# EFR32BG24A010F1024IM40 register map
Vendor: Silicon Labs; Series: EFR32; File version: B
Registers are 32-bit, read-write, reset 0x0 unless marked. A register's access mark holds for its fields unless they carry their own. Offsets are from the block's base; [hi:lo] are bit positions; {n}, {i} and the like mark numbered series; 'fields as' and 'values as' point back to an identical list.

## HOSTMAILBOX_S — HOSTMAILBOX_S Registers
Base 0x40098000
Same registers: HOSTMAILBOX_NS 0x50098000, RFMAILBOX_S 0xA802C000, RFMAILBOX_NS 0xB802C000
{0x0+4i} MSGPTR{i} (i=0..3)
  [31:0] PTR — Pointer
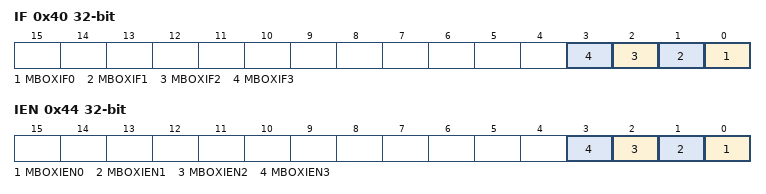
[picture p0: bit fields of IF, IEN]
0x40 IF
  [n] MBOXIF{n} (n=0..3) — Mailbox Interupt Flag
0x44 IEN
  [n] MBOXIEN{n} (n=0..3) — Mailbox Interrupt Enable

## SYSRTC0_S — SYSRTC0_S Registers
Base 0x400A8000
Same registers: SYSRTC0_NS 0x500A8000
0x00 IPVERSION ro reset 0x1
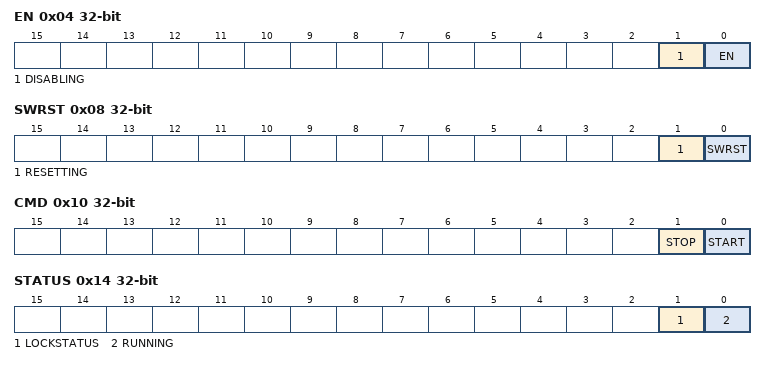
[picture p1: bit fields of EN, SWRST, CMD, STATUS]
0x04 EN
  [1] DISABLING ro — Disablement busy status
  [0] EN — SYSRTC Enable
0x08 SWRST
  [1] RESETTING ro — Software reset busy status
  [0] SWRST wo — Software reset command
0x0C CFG
  [0] DEBUGRUN — Debug Mode Run Enable
    0=DISABLE (SYSRTC is frozen in debug mode); 1=ENABLE (SYSRTC is running in debug mode)
0x10 CMD wo
  [1] STOP — Stop SYSRTC
  [0] START — Start SYSRTC
0x14 STATUS ro
  [1] LOCKSTATUS
    0=UNLOCKED (SYSRTC registers are unlocked); 1=LOCKED (SYSRTC registers are locked)
  [0] RUNNING — SYSRTC running status
0x18 CNT
  [31:0] CNT — Counter Value
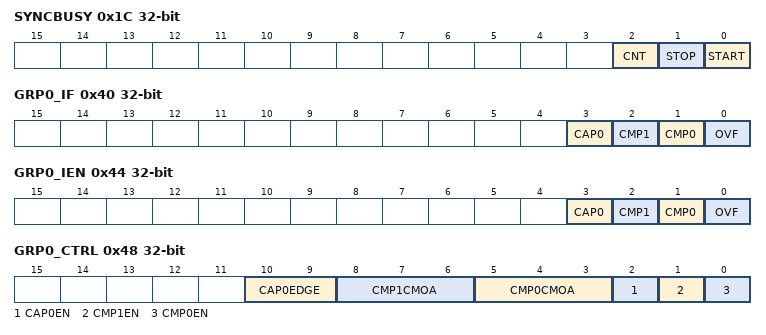
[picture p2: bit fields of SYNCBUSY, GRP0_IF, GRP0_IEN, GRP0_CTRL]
0x1C SYNCBUSY ro
  [2] CNT — Sync busy for CNT bitfield
  [1] STOP — Sync busy for STOP bitfield
  [0] START — Sync busy for START bitfield
0x20 LOCK wo
  [15:0] LOCKKEY — Configuration Lock Key
    0x4776=UNLOCK (Write to unlock SYSRTC lockable registers)
0x40 GRP0_IF
  [3] CAP0 — Capture 0 Interrupt Flag
  [2] CMP1 — Compare 1 Interrupt Flag
  [1] CMP0 — Compare 0 Interrupt Flag
  [0] OVF — Overflow Interrupt Flag
0x44 GRP0_IEN
  [3] CAP0 — Capture 0 Interrupt Enable
  [2] CMP1 — Compare 1 Interrupt Enable
  [1] CMP0 — Compare 0 Interrupt Enable
  [0] OVF — Overflow Interrupt Enable
0x48 GRP0_CTRL
  [10:9] CAP0EDGE — Capture 0 Edge Select
    0=RISING (Rising edges detected); 1=FALLING (Falling edges detected); 2=BOTH (Both edges detected)
  [8:6] CMP1CMOA — Compare 1 Compare Match Output Action
    0=CLEAR (Cleared on the next cycle); 1=SET (Set on the next cycle); 2=PULSE (Set on the next cycle, cleared on the cycle after); 3=TOGGLE (Inverted on the next cycle); 4=CMPIF (Export this channel's CMP IF)
  [5:3] CMP0CMOA — Compare 0 Compare Match Output Action
    values as CMP1CMOA
  [2] CAP0EN — Capture 0 Enable
  [1] CMP1EN — Compare 1 Enable
  [0] CMP0EN — Compare 0 Enable
0x4C GRP0_CMP0VALUE
  [31:0] CMP0VALUE — Compare 0 Value
0x50 GRP0_CMP1VALUE
  [31:0] CMP1VALUE — Compare 1 Value
0x54 GRP0_CAP0VALUE ro
  [31:0] CAP0VALUE — Capture 0 Value
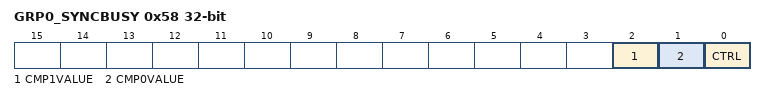
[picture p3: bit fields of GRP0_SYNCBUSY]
0x58 GRP0_SYNCBUSY ro
  [2] CMP1VALUE — Sync busy for CMP1VALUE register
  [1] CMP0VALUE — Sync busy for CMP0VALUE register
  [0] CTRL — Sync busy for CTRL register

## KEYSCAN_S — KEYSCAN_S Registers
Base 0x400B0000
Same registers: KEYSCAN_NS 0x500B0000
0x00 IPVERSION ro reset 0x1
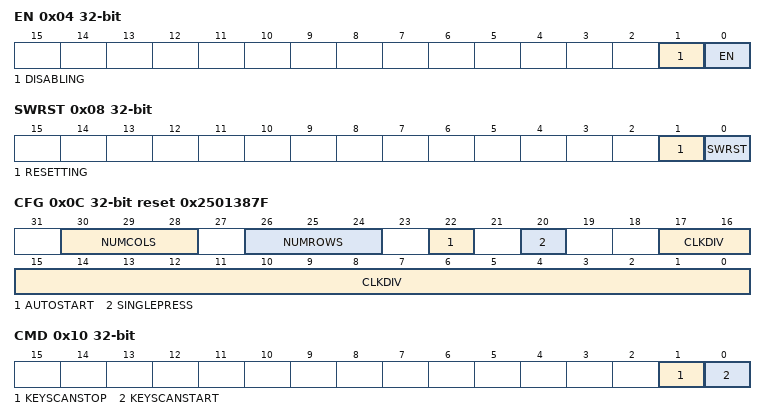
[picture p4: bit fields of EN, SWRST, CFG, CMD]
0x04 EN — Enable
  [1] DISABLING ro — Disablement busy status
  [0] EN — Enable
    0=DISABLE (Stops clocking and resets peripheral core logic.); 1=ENABLE (Enables clocking, and begins scanning if CFG.AUTOSTART is 0x1.)
0x08 SWRST — Software Reset
  [1] RESETTING ro — Software reset busy status
  [0] SWRST wo — Software reset command
0x0C CFG reset 0x2501387F — Config
  [30:28] NUMCOLS — Number of Columns
  [26:24] NUMROWS — Number of Rows
    0=RSV1 (1 Row is not supported; defaults to 3 instead); 1=RSV2 (2 Rows are not supported; defaults to 3 instead); {v}=ROW{v+1} ({v+1} Rows) (v=2..5)
  [22] AUTOSTART — Automatically Start
    0=AUTOSTARTDIS (Auto start is disabled); 1=AUTOSTARTEN (Auto start is enabled)
  [20] SINGLEPRESS
    0=MULTIPRESS (After KEYIF is set and then cleared, scanning will continue. This can give multiple interrupts for the same key press, but allow multiple key presses to be detected. To use this mode for multi-key detection, the ISR should update a section of memory of COLNUM bytes on each interrupt, until key release is detected. After key release, the section of memory where key presses are recorded can be processed.); 1=SINGLEPRESS (After KEYIF has been set and cleared, it will not set again until no key press is detected. This allows faster response since the ISR can start processing data as soon as the KEYIF is set.)
  [17:0] CLKDIV — Clock Divider
0x10 CMD wo — Command
  [1] KEYSCANSTOP, [0] KEYSCANSTART
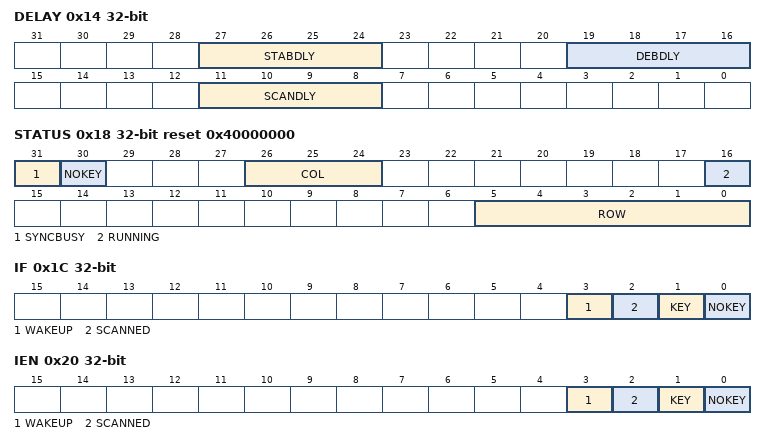
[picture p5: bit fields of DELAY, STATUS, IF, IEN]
0x14 DELAY
  [27:24] STABDLY — Row stable Delay
    0=2ms Row Stable Delay; 1=4ms Row Stable Delay; 2=6ms Row Stable Delay; 3=8ms Row Stable Delay; 4=10ms Row Stable Delay; 5=12ms Row Stable Delay; 6=14ms Row Stable Delay; 7=16ms Row Stable Delay; 8=18ms Row Stable Delay; 9=20ms Row Stable Delay; 10=22ms Row Stable Delay; 11=24ms Row Stable Delay; 12=26ms Row Stable Delay; 13=28ms Row Stable Delay; 14=30ms Row Stable Delay; 15=32ms Row Stable Delay
  [19:16] DEBDLY — Debounce Delay
    0=2ms Debounce Delay; 1=4ms Debounce Delay; 2=6ms Debounce Delay; 3=8ms Debounce Delay; 4=10ms Debounce Delay; 5=12ms Debounce Delay; 6=14ms Debounce Delay; 7=16ms Debounce Delay; 8=18ms Debounce Delay; 9=20ms Debounce Delay; 10=22ms Debounce Delay; 11=24ms Debounce Delay; 12=26ms Debounce Delay; 13=28ms Debounce Delay; 14=30ms Debounce Delay; 15=32ms Debounce Delay
  [11:8] SCANDLY — Scan Delay
    0=2ms Scan Delay; 1=4ms Scan Delay; 2=6ms Scan Delay; 3=8ms Scan Delay; 4=10ms Scan Delay; 5=12ms Scan Delay; 6=14ms Scan Delay; 7=16ms Scan Delay; 8=18ms Scan Delay; 9=20ms Scan Delay; 10=22ms Scan Delay; 11=24ms Scan Delay; 12=26ms Scan Delay; 13=28ms Scan Delay; 14=30ms Scan Delay; 15=32ms Scan Delay
0x18 STATUS ro reset 0x40000000
  [31] SYNCBUSY
  [30] NOKEY — No Key pressed status
  [26:24] COL — Column Latched
  [16] RUNNING
  [5:0] ROW — Row detection
0x1C IF — Interrupt Flags
  [3] WAKEUP
  [2] SCANNED — Completed scan
  [1] KEY — A key was pressed
  [0] NOKEY — No key was pressed
0x20 IEN — Interrupt Enables
  [3] WAKEUP
  [2] SCANNED — Completed Scanning
  [1] KEY — A Key was pressed
  [0] NOKEY — No Key was pressed
